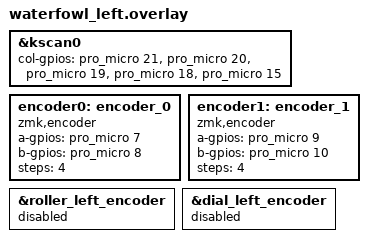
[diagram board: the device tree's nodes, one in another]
/*
 * Copyright (c) 2022 The ZMK Contributors
 *
 * SPDX-License-Identifier: MIT
 */

#include "waterfowl.dtsi"

&kscan0 {
    col-gpios
        = <&pro_micro 21 GPIO_ACTIVE_HIGH>
        , <&pro_micro 20 GPIO_ACTIVE_HIGH>
        , <&pro_micro 19 GPIO_ACTIVE_HIGH>
        , <&pro_micro 18 GPIO_ACTIVE_HIGH>
        , <&pro_micro 15 GPIO_ACTIVE_HIGH>
        ;
};

/* --- Encoder 0 (oben links) --- */
encoder0: encoder_0 {
    compatible = "zmk,encoder";
    a-gpios = <&pro_micro 7 GPIO_ACTIVE_HIGH>;
    b-gpios = <&pro_micro 8 GPIO_ACTIVE_HIGH>;
    steps = <4>;
};

/* --- Encoder 1 (unten links) --- */
encoder1: encoder_1 {
    compatible = "zmk,encoder";
    a-gpios = <&pro_micro 9 GPIO_ACTIVE_HIGH>;
    b-gpios = <&pro_micro 10 GPIO_ACTIVE_HIGH>;
    steps = <4>;
};

/* Original Nodes */
&roller_left_encoder {
    status = "disabled";
};

&dial_left_encoder {
    status = "disabled";
};
